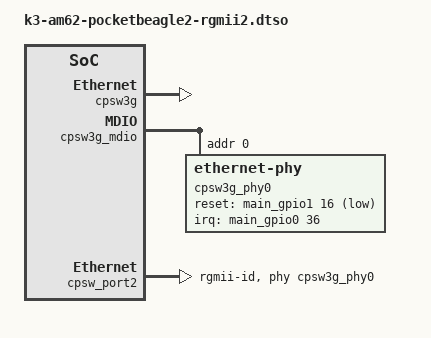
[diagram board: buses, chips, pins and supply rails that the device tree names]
// SPDX-License-Identifier: GPL-2.0-only OR MIT
/*
 * DT Overlay for ethernet with rgmii2 connections within the expansion header.
 *
 */

/dts-v1/;
/plugin/;

#include <dt-bindings/gpio/gpio.h>
#include <dt-bindings/interrupt-controller/irq.h>
#include <dt-bindings/net/ti-dp83867.h>
#include "ti/k3-pinctrl.h"

/*
 * Helper to show loaded overlays under: /proc/device-tree/chosen/overlays/
*/
&{/chosen} {
	overlays {
		k3-am62-pocketbeagle2-rgmii2.kernel = __TIMESTAMP__;
	};
};

&main_pmx0 {

	main_spi0_pins_no_cs: main-spi0-no-cs-pins {
		pinctrl-single,pins = <
			AM62X_IOPAD(0x01bc, PIN_INPUT, 0) /* (A14) SPI0_CLK */
			AM62X_IOPAD(0x01c0, PIN_OUTPUT, 0) /* (B13) SPI0_D0 */
			AM62X_IOPAD(0x01c4, PIN_INPUT, 0) /* (B14) SPI0_D1 */
			//Disable chip select  AM62X_IOPAD(0x01b4, PIN_OUTPUT, 0) /* (A13) SPI0_CS0 */
		>;
	};

	rgmii2_pins_default: rgmii2-default-pins {
		pinctrl-single,pins = <

			AM62X_IOPAD(0x0168, PIN_OUTPUT, 0) /* (AE21) RGMII2_TXC.GPIO0_88 */

			AM62X_IOPAD(0x0164, PIN_OUTPUT, 0) /* (AA19) RGMII2_TX_CTL.GPIO0_87 */
			AM62X_IOPAD(0x01A0, PIN_DISABLE, 7) /* (E18) MCASP0_AXR0.GPIO1_10 */

			AM62X_IOPAD(0x016C, PIN_OUTPUT, 0) /* (Y18) RGMII2_TD0.GPIO0_89 */
			AM62X_IOPAD(0x01A8, PIN_DISABLE, 7) /* (D20) MCASP0_AFSX.GPIO1_12 */

			AM62X_IOPAD(0x0170, PIN_OUTPUT, 0) /* (AA18) RGMII2_TD1.GPIO0_90 */
			AM62X_IOPAD(0x01B4, PIN_DISABLE, 7) /* (A13) SPI0_CS0.GPIO1_15 */

			AM62X_IOPAD(0x0174, PIN_OUTPUT, 0) /* (AD21) RGMII2_TD2.GPIO0_91 */
			AM62X_IOPAD(0x0178, PIN_OUTPUT, 0) /* (AC20) RGMII2_TD3.GPIO1_0 */

			AM62X_IOPAD(0x0180, PIN_INPUT, 0) /* (AD23) RGMII2_RXC.GPIO1_2 */
			AM62X_IOPAD(0x017C, PIN_INPUT, 0) /* (AD22) RGMII2_RX_CTL.GPIO1_1 */
			AM62X_IOPAD(0x0190, PIN_INPUT, 0) /* (AE22) RGMII2_RD3.GPIO1_6 */
			AM62X_IOPAD(0x018C, PIN_INPUT, 0) /* (AC21) RGMII2_RD2.GPIO1_5 */
			AM62X_IOPAD(0x0188, PIN_INPUT, 0) /* (AB20) RGMII2_RD1.GPIO1_4 */
			AM62X_IOPAD(0x0184, PIN_INPUT, 0) /* (AE23) RGMII2_RD0.GPIO1_3 */
		>;
	};

	mdio_pins_default: mdio-default-pins {
		pinctrl-single,pins = <
			AM62X_IOPAD(0x015C, PIN_INPUT, 0) /* (AB22) MDIO0_MDIO.GPIO0_85 */
			AM62X_IOPAD(0x019C, PIN_DISABLE, 7) /* (B18) MCASP0_AXR1.GPIO1_9 */

			AM62X_IOPAD(0x0160, PIN_OUTPUT, 0) /* (AD24) MDIO0_MDC.GPIO0_86 */
			AM62X_IOPAD(0x01A4, PIN_DISABLE, 7) /* (B20) MCASP0_ACLKX.GPIO1_11 */

			//rst
			AM62X_IOPAD(0x01B8, PIN_OUTPUT, 7) /* (C13) SPI0_CS1.GPIO1_16 */
			//int
			AM62X_IOPAD(0x0094, PIN_INPUT, 7) /* (N20) GPMC0_DIR.GPIO0_36 */
		>;
	};

};



&cpsw3g {
	pinctrl-names = "default";
	pinctrl-0 = <&rgmii2_pins_default>;
	status = "okay";
};

&cpsw3g_mdio {
	#address-cells = <1>;
	#size-cells = <0>;

	pinctrl-names = "default";
	pinctrl-0 = <&mdio_pins_default>; 
	status = "okay";

	cpsw3g_phy0: ethernet-phy@0 {
		reg = <0>;
		ti,rx-internal-delay = <DP83867_RGMIIDCTL_2_00_NS>;
		ti,fifo-depth = <DP83867_PHYCR_FIFO_DEPTH_4_B_NIB>;
		ti,min-output-impedance;

        /* 
         * Map the physical INT pin to an SoC GPIO bank.
         * Example: Main Domain GPIO bank 0, Pin 36, Active Low 
         */
        interrupt-parent = <&main_gpio0>;
        interrupts = <36 IRQ_TYPE_EDGE_FALLING>;

        /* Optional hardware reset configuration */
		reset-gpios = <&main_gpio1 16 GPIO_ACTIVE_LOW>;
		reset-assert-us = <10000>;
		reset-deassert-us = <50000>;
	};
};

&cpsw_port2 {
	phy-mode = "rgmii-id";
	phy-handle = <&cpsw3g_phy0>;
	status = "okay";
	ti,syscon-efuse = <&cpsw_mac_syscon 0x0>;
};

&main_spi0 {
	pinctrl-names = "default";
	pinctrl-0 = <&main_spi0_pins_no_cs>;
};

&ecap2 {
	status = "disable";
};
